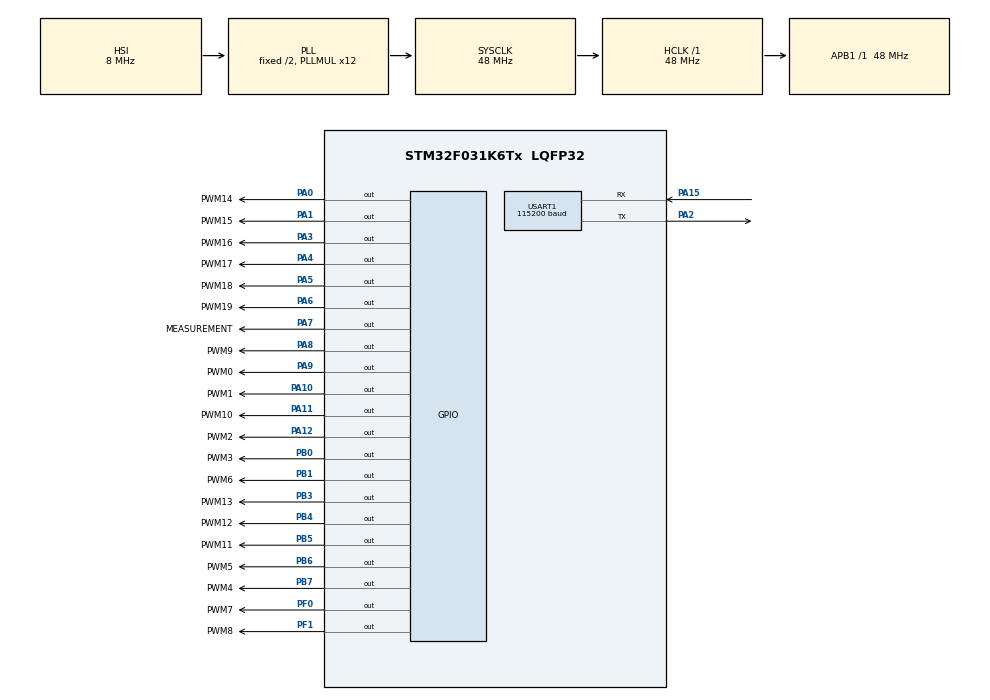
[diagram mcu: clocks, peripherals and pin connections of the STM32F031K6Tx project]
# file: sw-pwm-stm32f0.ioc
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Mcu.Family=STM32F0
Mcu.Name=STM32F031K6Tx
Mcu.Package=LQFP32
NVIC.TIM17_IRQn=true\:0\:0\:false\:false\:true\:true\:true
PA0.GPIO_Label=PWM14
PA0.Signal=GPIO_Output
PA1.GPIO_Label=PWM15
PA1.Signal=GPIO_Output
PA10.GPIO_Label=PWM1
PA10.Signal=GPIO_Output
PA11.GPIO_Label=PWM10
PA11.Signal=GPIO_Output
PA12.GPIO_Label=PWM2
PA12.Signal=GPIO_Output
PA13.Mode=Serial_Wire
PA13.Signal=SYS_SWDIO
PA14.Mode=Serial_Wire
PA14.Signal=SYS_SWCLK
PA15.Mode=Asynchronous
PA15.Signal=USART1_RX
PA2.Mode=Asynchronous
PA2.Signal=USART1_TX
PA3.GPIO_Label=PWM16
PA3.Signal=GPIO_Output
PA4.GPIO_Label=PWM17
PA4.Signal=GPIO_Output
PA5.GPIO_Label=PWM18
PA5.Signal=GPIO_Output
PA6.GPIO_Label=PWM19
PA6.Signal=GPIO_Output
PA7.GPIO_Label=MEASUREMENT
PA7.GPIO_Speed=GPIO_SPEED_FREQ_HIGH
PA7.Signal=GPIO_Output
PA8.GPIO_Label=PWM9
PA8.Signal=GPIO_Output
PA9.GPIO_Label=PWM0
PA9.Signal=GPIO_Output
PB0.GPIO_Label=PWM3
PB0.Signal=GPIO_Output
PB1.GPIO_Label=PWM6
PB1.Signal=GPIO_Output
PB3.GPIO_Label=PWM13
PB3.Signal=GPIO_Output
PB4.GPIO_Label=PWM12
PB4.Signal=GPIO_Output
PB5.GPIO_Label=PWM11
PB5.Signal=GPIO_Output
PB6.GPIO_Label=PWM5
PB6.Signal=GPIO_Output
PB7.GPIO_Label=PWM4
PB7.Signal=GPIO_Output
PF0-OSC_IN.GPIO_Label=PWM7
PF0-OSC_IN.Signal=GPIO_Output
PF1-OSC_OUT.GPIO_Label=PWM8
PF1-OSC_OUT.Signal=GPIO_Output
ProjectManager.HeapSize=0x200
ProjectManager.StackSize=0x400
ProjectManager.TargetToolchain=Makefile
RCC.AHBFreq_Value=48000000
RCC.APB1Freq_Value=48000000
RCC.APB1TimFreq_Value=48000000
RCC.HCLKFreq_Value=48000000
RCC.PLLMUL=RCC_PLL_MUL12
RCC.SYSCLKFreq_VALUE=48000000
RCC.SYSCLKSource=RCC_SYSCLKSOURCE_PLLCLK
TIM17.AutoReloadPreload=TIM_AUTORELOAD_PRELOAD_DISABLE
TIM17.Period=0xFFFF
USART1.BaudRate=115200
USART1.VirtualMode-Asynchronous=VM_ASYNC
VP_TIM17_VS_ClockSourceINT.Mode=Enable_Timer
board=custom

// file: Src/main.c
/* USER CODE BEGIN Header */

/**
 ******************************************************************************
 * @file           : main.c
 * @brief          : Main program body
 ******************************************************************************
 * @attention
 *
 * <h2><center>&copy; Copyright (c) 2020 STMicroelectronics.
 * All rights reserved.</center></h2>
 *
 * This software component is licensed by ST under BSD 3-Clause license,
 * the "License"; You may not use this file except in compliance with the
 * License. You may obtain a copy of the License at:
 *                        opensource.org/licenses/BSD-3-Clause
 *
 ******************************************************************************
 */
/* USER CODE END Header */

#include "main.h"
#include "tim.h"
#include "usart.h"
#include "gpio.h"

/* USER CODE BEGIN Includes */
#include "setup.h"
#include "super-loop.h"
/* USER CODE END Includes */

void SystemClock_Config(void);

int main(void)
{

    /* MCU Configuration--------------------------------------------------------*/

    /* Reset of all peripherals, Initializes the Flash interface and the Systick. */
    HAL_Init();

    /* Configure the system clock */
    SystemClock_Config();

    /* Initialize all configured peripherals */
    MX_GPIO_Init();
    MX_TIM17_Init();
    MX_USART1_UART_Init();
    /* USER CODE BEGIN 2 */
    setup();
    super_loop();
    /* USER CODE END 2 */

    /* Infinite loop */
    while (1)
    {

    }
} /* main */

void SystemClock_Config(void)
{
    RCC_OscInitTypeDef RCC_OscInitStruct   = { 0 };
    RCC_ClkInitTypeDef RCC_ClkInitStruct   = { 0 };
    RCC_PeriphCLKInitTypeDef PeriphClkInit = { 0 };

    /** Initializes the CPU, AHB and APB busses clocks
     */
    RCC_OscInitStruct.OscillatorType      = RCC_OSCILLATORTYPE_HSI;
    RCC_OscInitStruct.HSIState            = RCC_HSI_ON;
    RCC_OscInitStruct.HSICalibrationValue = RCC_HSICALIBRATION_DEFAULT;
    RCC_OscInitStruct.PLL.PLLState        = RCC_PLL_ON;
    RCC_OscInitStruct.PLL.PLLSource       = RCC_PLLSOURCE_HSI;
    RCC_OscInitStruct.PLL.PLLMUL          = RCC_PLL_MUL12;
    RCC_OscInitStruct.PLL.PREDIV          = RCC_PREDIV_DIV1;
    if (HAL_RCC_OscConfig(&RCC_OscInitStruct) != HAL_OK)
    {
        Error_Handler();
    }

    /** Initializes the CPU, AHB and APB busses clocks
     */
    RCC_ClkInitStruct.ClockType = RCC_CLOCKTYPE_HCLK | RCC_CLOCKTYPE_SYSCLK
      | RCC_CLOCKTYPE_PCLK1;
    RCC_ClkInitStruct.SYSCLKSource   = RCC_SYSCLKSOURCE_PLLCLK;
    RCC_ClkInitStruct.AHBCLKDivider  = RCC_SYSCLK_DIV1;
    RCC_ClkInitStruct.APB1CLKDivider = RCC_HCLK_DIV1;

    if (HAL_RCC_ClockConfig(&RCC_ClkInitStruct, FLASH_LATENCY_1) != HAL_OK)
    {
        Error_Handler();
    }
    PeriphClkInit.PeriphClockSelection = RCC_PERIPHCLK_USART1;
    PeriphClkInit.Usart1ClockSelection = RCC_USART1CLKSOURCE_PCLK1;
    if (HAL_RCCEx_PeriphCLKConfig(&PeriphClkInit) != HAL_OK)
    {
        Error_Handler();
    }
} /* SystemClock_Config */

void Error_Handler(void)
{
}

#ifdef  USE_FULL_ASSERT

/**
 * @brief  Reports the name of the source file and the source line number
 *         where the assert_param error has occurred.
 * @param  file: pointer to the source file name
 * @param  line: assert_param error line source number
 * @retval None
 */
void assert_failed(char *file, uint32_t line)
{
    /* USER CODE BEGIN 6 */

    /* User can add his own implementation to report the file name and line number,
     * tex: printf("Wrong parameters value: file %s on line %d\r\n", file, line) */
    /* USER CODE END 6 */
}

#endif /* USE_FULL_ASSERT */

/************************ (C) COPYRIGHT STMicroelectronics *****END OF FILE****/
